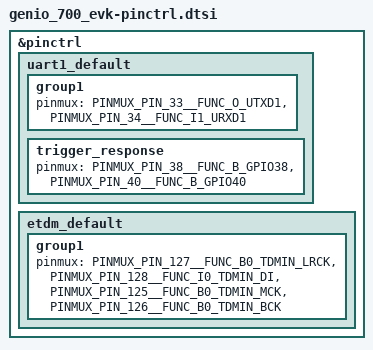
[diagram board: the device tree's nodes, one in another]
/*
 * Copyright (c) 2025 MediaTek
 *
 * SPDX-License-Identifier: Apache-2.0
 */

#include <dt-bindings/pinctrl/mt8188-pinctrl.h>
#include <zephyr/dt-bindings/pinctrl/mt8188-pinctrl.h>

&pinctrl {
	uart1_default: uart1_default {
		group1 {
			pinmux = <PINMUX_PIN_33__FUNC_O_UTXD1>,
				 <PINMUX_PIN_34__FUNC_I1_URXD1>;
		};

		trigger_response {
			pinmux = <PINMUX_PIN_38__FUNC_B_GPIO38>,
				 <PINMUX_PIN_40__FUNC_B_GPIO40>;
		};
	};

	etdm_default: etdm_default {
		group1 {
			pinmux = <PINMUX_PIN_127__FUNC_B0_TDMIN_LRCK>,
				 <PINMUX_PIN_128__FUNC_I0_TDMIN_DI>,
				 <PINMUX_PIN_125__FUNC_B0_TDMIN_MCK>,
				 <PINMUX_PIN_126__FUNC_B0_TDMIN_BCK>;
		};
	};
};
